# DA14682 register map
Vendor: Dialog; Series: DA14682; File version: 1.2
CPU: CM0 r1p0, little endian, MPU, FPU, 3 interrupt priority bits
Registers are 16-bit, read-write, reset 0x0 unless marked. A register's access mark holds for its fields unless they carry their own. Offsets are from the block's base; [hi:lo] are bit positions; {n}, {i} and the like mark numbered series; 'fields as' and 'values as' point back to an identical list.

## FTDF — FTDF registers
Base 0x40080000
{0x0+0x80*i} FTDF_TX_FIFO_{i}_0_REG 32-bit (reset mask 0x7FFFFFFF) (i=0..3) — Address transmit fifo {i}
  [31:0] TX_FIFO — Transmit fifo buffer, contains 32 addresses per entry (32b x 32a = 128B). There are 4 entries supported. Note that, despite the name, this fifo is NOT retained when the LMAC is put into deep-sleep!
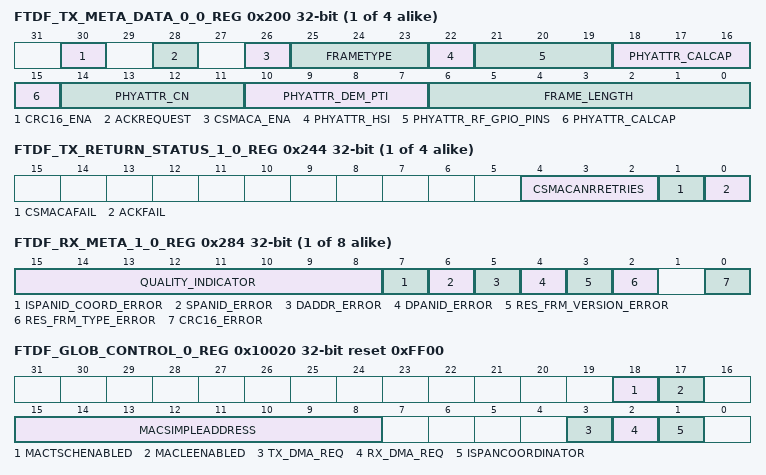
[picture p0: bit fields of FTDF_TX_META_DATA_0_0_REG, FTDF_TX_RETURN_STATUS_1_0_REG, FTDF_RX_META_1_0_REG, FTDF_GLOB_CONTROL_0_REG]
{0x200+0x10*i} FTDF_TX_META_DATA_0_{i}_REG 32-bit (i=0..3) — Transmit metadata register {i}
  [30] CRC16_ENA — Tx meta data per entry: Indicates whether CRC16 insertion must be enabled or not. 0 : No hardware inserted CRC16 1 : Hardware inserts CRC16
  [28] ACKREQUEST — Tx meta data per entry: '1' indicates that an acknowledge is expected from the recipient of this packet.
  [26] CSMACA_ENA — Tx meta data per entry: '1' indicates that a CSMA-CA is required for the transmission of this packet.
  [25:23] FRAMETYPE — Tx meta data per entry: the frame type of the data to be transmitted (Data/Cmd/Ack/wakeup frame/etc.).
  [22] PHYATTR_HSI — HighSide injection.
  [21:19] PHYATTR_RF_GPIO_PINS — Slot-basis signals mapped on GPIO via PPA.
  [18:15] PHYATTR_CALCAP — CalCap value.
  [14:11] PHYATTR_CN — Channel Number.
  [10:7] PHYATTR_DEM_PTI — DEM packet information.
  [6:0] FRAME_LENGTH — Tx meta data per entry: Frame length (in bytes)
{0x204+0x10*i} FTDF_TX_META_DATA_1_{i}_REG 32-bit (i=0..3) — Transmit metadata register {i}
  [7:0] MACSN — Tx meta data per entry: Sequence Number of this packet.
{0x240+0x10*i} FTDF_TX_RETURN_STATUS_0_{i}_REG 32-bit (reset mask 0x7FFFFFFF) (i=0..3) — Transmit status register {i}
  [31:0] TXTIMESTAMP ro — Tx return status per entry: Transmit Timestamp The Timestamp of the transmitted packet.
{0x244+0x10*i} FTDF_TX_RETURN_STATUS_1_{i}_REG 32-bit (i=0..3) — Transmit status register {i}
  [4:2] CSMACANRRETRIES ro — Tx return status per entry: Number of CSMA-CA retries before this frame has been transmitted
  [1] CSMACAFAIL ro — Tx return status per entry: CSMA-CA status 0 : SUCCESS 1 : FAIL
  [0] ACKFAIL ro — Tx return status per entry: Acknowledgement status 0 : SUCCESS 1 : FAIL
{0x280+0x10*i} FTDF_RX_META_0_{i}_REG 32-bit (reset mask 0x7FFFFFFF) (i=0..7) — Receive metadata register {i}
  [31:0] RX_TIMESTAMP ro — Rx meta data per entry: Timestamp taken when frame was received
{0x284+0x10*i} FTDF_RX_META_1_{i}_REG 32-bit (i=0..7) — Receive metadata register {i}
  [15:8] QUALITY_INDICATOR ro — Rx meta data per entry: the Link Quality Indication value during reception of this frame. # $software_scratch@retention_ram # TX ram not used by hardware, can be used by software as scratch ram with retention.
  [7] ISPANID_COORD_ERROR ro — Rx meta data per entry: if set to '1', the received frame is not for PAN coordinator, applicable when frame is not discarded
  [6] SPANID_ERROR ro — Rx meta data per entry: if set to '1', a PAN ID error has occurred, applicable when frame is not discarded
  [5] DADDR_ERROR ro — Rx meta data per entry: if set to '1', a destination Address error has occurred, applicable when frame is not discarded
  [4] DPANID_ERROR ro — Rx meta data per entry: if set to '1', a destination PAN ID error has occurred, applicable when frame is not discarded
  [3] RES_FRM_VERSION_ERROR ro — Rx meta data per entry: if set to '1' this frame is a not supported frame version, applicable when frame is not discarded.
  [2] RES_FRM_TYPE_ERROR ro — Rx meta data per entry: if set to '1' this frame is a not supported frame type, applicable when frame is not discarded
  [0] CRC16_ERROR ro — Rx meta data per entry: if set, a CRC error has occurred in this frame, applicable for transparent mode only
0x8000 FTDF_RX_FIFO_0_0_REG 32-bit (reset mask 0x7FFFFFFF) — Address receive fifo 0
  [31:0] RX_FIFO — Receive fifo ram, contains 32 addresses per entry (32b x 32a = 128B). There are 8 entries supported.
{0x8000+0x80*i} FTDF_RX_FIFO_{i}_0_REG 32-bit (reset mask 0x7FFFFFFF) (i=1..7) — Address transmit fifo {i}
  fields as FTDF_RX_FIFO_0_0_REG
{0x10000+4i} FTDF_REL_NAME_{i}_REG 32-bit (reset mask 0x7FFFFFFF) (i=0..3) — Name of the release
  [31:0] REL_NAME ro — A 4 words wide register, showing in ASCII the name of the release, eg. ftdf_107.
{0x10010+4i} FTDF_BUILDTIME_{i}_REG 32-bit (reset mask 0x7FFFFFFF) (i=0..3) — Build time
  [31:0] BUILDTIME ro — A 4 words wide register, showing in ASCII the build date (dd mmm yy) and time (hh:mm) of device, eg. 01 Dec 14 14:10.
0x10020 FTDF_GLOB_CONTROL_0_REG 32-bit reset 0xFF00 — Global control register
  [18] MACTSCHENABLED — If set to '1', the TSCH mode is enabled
  [17] MACLEENABLED — If set to '1', the Low Energy mode (also called CSL) is enabled
  [15:8] MACSIMPLEADDRESS — Simple address of the PAN coordinator
  [3] TX_DMA_REQ — Source of the TX_DMA_REQ output pin of this block.
  [2] RX_DMA_REQ — Source of the RX_DMA_REQ output pin of this block.
  [1] ISPANCOORDINATOR — Enable/disable receiver check on address fields (0=enabled, 1=disabled)
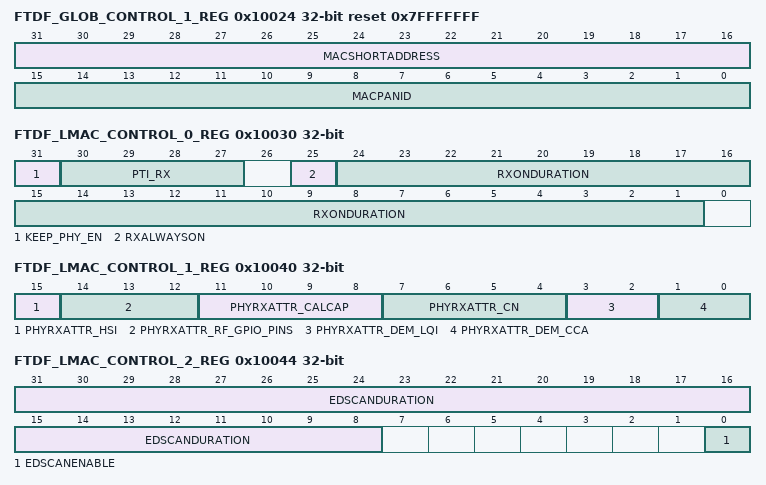
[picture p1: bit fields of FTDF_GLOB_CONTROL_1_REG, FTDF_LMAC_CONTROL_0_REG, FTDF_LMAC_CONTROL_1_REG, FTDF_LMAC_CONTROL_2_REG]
0x10024 FTDF_GLOB_CONTROL_1_REG 32-bit reset 0x7FFFFFFF (reset mask 0x7FFFFFFF) — Global control register
  [31:16] MACSHORTADDRESS — The short address of the device. The values 0xFFFF and 0xFFFE indicate that no IEEE Short Address is available.
  [15:0] MACPANID — The PAN ID of this device. The value 0xFFFF indicates that the device is not associated to a PAN.
0x10028 FTDF_GLOB_CONTROL_2_REG 32-bit reset 0x7FFFFFFF (reset mask 0x7FFFFFFF) — Global control register
  [31:0] AEXTENDEDADDRESS_L — Unique device address, 48 bits wide, lowest 32 bit
0x1002C FTDF_GLOB_CONTROL_3_REG 32-bit reset 0x7FFFFFFF (reset mask 0x7FFFFFFF) — Global control register
  [31:0] AEXTENDEDADDRESS_H — Unique device address, 48 bits wide, highest 16 bit
0x10030 FTDF_LMAC_CONTROL_0_REG 32-bit (reset mask 0x7FFFFFFF) — Lmac control register
  [31] KEEP_PHY_EN — When the transmit or receive action is ready (LmacReady4Sleep is set), the PHY_EN signal is cleared unless the control register keep_phy_en is set to '1'. When the control register keep_phy_en is set to '1', the signal PHY_EN shall remain being set until the keep_phy_en is cleared. This will help control the behavior of the arbiter between the LMAC and the DPHY.
  [30:27] PTI_RX — This value will be used during receiving frames, during the auto ACK (when the AR bit is set in the received frame, see [FR0655] and further), a single CCA and ED scan. In TSCH mode this register will be used during the time slot in which frames can be received and consequently an Enhanced ACK can be transmitted.
  [25] RXALWAYSON — If set to '1', the receiver shall be always on if RxEnable is set to '1'.
  [24:1] RXONDURATION — The time (in symbol periods) the Rx must be on after setting RxEnable to '1'.
0x10034 FTDF_TXPIPEPROPDELAY_REG 32-bit — Prop delay transmit register
  [7:0] TXPIPEPROPDELAY — Propagation delay (in us) of the tx pipe, between start of transmission (indicated by setting tx_flag_status) to the DPHY. The reset value is 0 us, which is also the closest value to the real implementation figure.
0x10038 FTDF_MACACKWAITDURATION_REG 32-bit reset 0x36 — Maximum time to wait for a ACK
  [7:0] MACACKWAITDURATION — Maximum time (in symbol periods) to wait for an ACK response after transmitting a frame with the AR bit set to '1'. This value is used in the normal mode for the wait of an ACK response, irrespective if the ACK is a normal ACK or an Enhanced ACK.
0x1003C FTDF_MACENHACKWAITDURATION_REG 32-bit reset 0x360 — Maximum time to wait for an enhanced ACK frame
  [15:0] MACENHACKWAITDURATION — Maximum time (in us) to wait for an Enhanced ACK response after transmitting a frame with the AR bit set to '1'. This value is used in the LE/CSL mode for the wait of an ACK response (which is always an Enhanced ACK).
0x10040 FTDF_LMAC_CONTROL_1_REG 32-bit — Lmac control register
  [15] PHYRXATTR_HSI — HighSide injection.
  [14:12] PHYRXATTR_RF_GPIO_PINS — Slot-basis signals mapped on GPIO via PPA.
  [11:8] PHYRXATTR_CALCAP — CalCap value.
  [7:4] PHYRXATTR_CN — Channel Number.
  [3:2] PHYRXATTR_DEM_LQI — Select the LQI calculation
  [1:0] PHYRXATTR_DEM_CCA
0x10044 FTDF_LMAC_CONTROL_2_REG 32-bit (reset mask 0x7FFFFFFF) — Lmac control register
  [31:8] EDSCANDURATION — The length of ED scan in symbol periods.
  [0] EDSCANENABLE — If set to '1', the Energy Detect scan will be performed when RxEnable is set to '1' rather than starting a receive action. The length of this scan is defined by EdScanDuration.
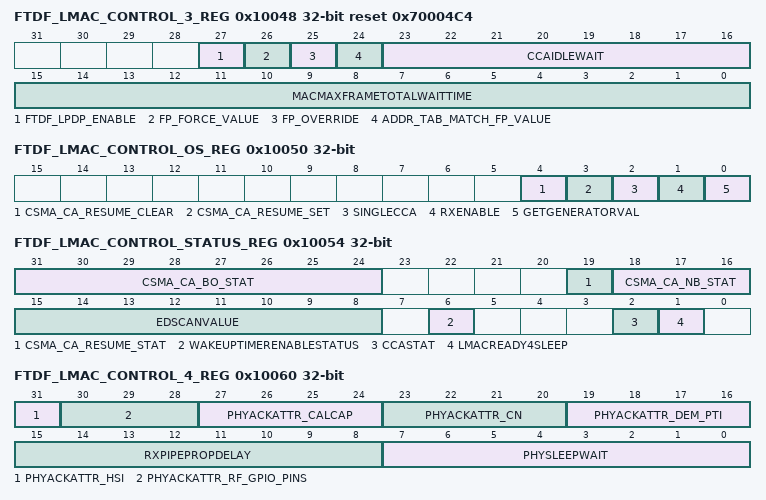
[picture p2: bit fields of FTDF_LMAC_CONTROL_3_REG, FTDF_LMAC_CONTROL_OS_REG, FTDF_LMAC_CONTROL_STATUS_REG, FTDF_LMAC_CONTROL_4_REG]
0x10048 FTDF_LMAC_CONTROL_3_REG 32-bit reset 0x70004C4 — Lmac control register
  [27] FTDF_LPDP_ENABLE — If set, not only is FP_override and SA matching done on data_request frames but to all command and data frame types (in normal mode)
  [26] FP_FORCE_VALUE — In case the control register FP_override is set, the value of the control register FP_force_value will always be the value of the FP bit in the automatic ACK response frame.
  [25] FP_OVERRIDE — In case the control register FP_override is set, the value of the control register FP_force_value will always be the value of the FP bit in the automatic ACK response frame.
  [24] ADDR_TAB_MATCH_FP_VALUE — In case the received source address matches with one of the Exp_SA registers, the value of the control register Addr_tap_match_FP_value will be inserted on the position of the FP bit. In case there is no match found, the inverse value of Addr_tap_match_FP_value will be inserted.
  [23:16] CCAIDLEWAIT — Time to wait (in us) after CCA returned medium idle before starting TX-ON. Notes: 1) extra wait times are involved before a packet is really transmitted, see the relevant timing figures. 2) not applicable in TSCH mode since there macTSRxTx shall be used.
  [15:0] MACMAXFRAMETOTALWAITTIME — Max time to wait (in symbol periods) for a requested Data Frame or an announced broadcast frame, triggered by the FP bit in the received frame was set to '1'.
0x10050 FTDF_LMAC_CONTROL_OS_REG 32-bit — Lmac control register
  [4] CSMA_CA_RESUME_CLEAR wo — If set, Csma_Ca_resume_stat is cleared
  [3] CSMA_CA_RESUME_SET wo — If set, Csma_Ca_resume_stat is set
  [2] SINGLECCA wo — If set to '1', a single CCA will be performed. This can be used when e.g. the TSCH timing is not performed by the LMAC but completely by software.
  [1] RXENABLE wo — If set, receiving data may be done
  [0] GETGENERATORVAL wo — If set to '1', the current values of the Wake-up (event) counter/generator (EventCurrVal) and Timestamp (symbol) counter/generator (TimeStampCurrVal and TimeStampCurrPhaseVal) will be captured. Note that this capture actually has been done when getGeneratorVal_e is set (assuming it was cleared in advance).
0x10054 FTDF_LMAC_CONTROL_STATUS_REG 32-bit (reset mask 0x7FFFFFFF) — Lmac status register
  [31:24] CSMA_CA_BO_STAT ro — The value of the currently calculated BackOff value. To be used for the sleep time calculation in case of sleep during the BackOff time.
  [19] CSMA_CA_RESUME_STAT ro — In case Csma_Ca_resume_stat is set the LMAC will - use the value of Csma_Ca_NB_val in the CSMA-CA process rather than the initial value 0d. - immediately perform CCA after the sleep, not waiting for the backoff time. - reset Csma_Ca_resume_stat when it resumes CSMA-CA after the sleep.
  [18:16] CSMA_CA_NB_STAT ro — Current status of the Number of Backoffs.
  [15:8] EDSCANVALUE ro — The result of an ED scan.
  [6] WAKEUPTIMERENABLESTATUS ro — Status of WakeupTimerEnable after being clocked by LP_CLK (showing it's effective value). WakeupTimerEnableStatus can be set by setting the one-shot register WakeupTimerEnable_set and cleared by setting the one-shot register WakeupTimerEnable_clear. When WakeupTimerEnableStatus is set (after being cleared), the event counter will be reset to 0x0. This status can be used by software since WakeupTimerEnable is used in the slow LP_CLK area. Rather than waiting for a certain number of LP_CLK periods, simply scanning this status (or enable the interrupt created by WakeupTimerEnableStatus_e) will allow software to determine if this signal has been effected. Note that the rising edge of WakeupTimerEnable will reset the Wake-up (event) counter.
  [2] CCASTAT ro — The value of a single CCA, valid when CCAstat_e is set to '1'.
  [1] LMACREADY4SLEEP ro — If set to '1' this register indicates that the LMAC is ready to go to sleep.
0x10058 FTDF_EVENTCURRVAL_REG 32-bit — Value of event generator
  [24:0] EVENTCURRVAL ro — The value of the captured Event generator (Wake-up counter) (initiated by getGeneratorVal, valid when getGeneratorVal_e is set).
0x1005C FTDF_TIMESTAMPCURRVAL_REG 32-bit (reset mask 0x7FFFFFFF) — Value of timestamp generator
  [31:0] TIMESTAMPCURRVAL ro — The value of captured timestamp generator (symbol counter) (initiated by getGeneratorVal, valid when getGeneratorVal_e is set)
0x10060 FTDF_LMAC_CONTROL_4_REG 32-bit (reset mask 0x7FFFFFFF) — Lmac control register
  [31] PHYACKATTR_HSI — HighSide injection.
  [30:28] PHYACKATTR_RF_GPIO_PINS — Slot-basis signals mapped on GPIO via PPA.
  [27:24] PHYACKATTR_CALCAP — CalCap value.
  [23:20] PHYACKATTR_CN — Channel Number.
  [19:16] PHYACKATTR_DEM_PTI — DEM packet information.
  [15:8] RXPIPEPROPDELAY — The control register RxPipePropDelay indicates the propagation delay in ~s of the Rx pipeline between the last symbol being captured at the DPHY interface and the data valid indication to the LMAC controller.
  [7:0] PHYSLEEPWAIT — The minume time (in us) required between the clear to '0' and set to '1' of PHY_EN. When the signal PHY_EN is deasserted, it will not be asserted within the time phySleepWait.
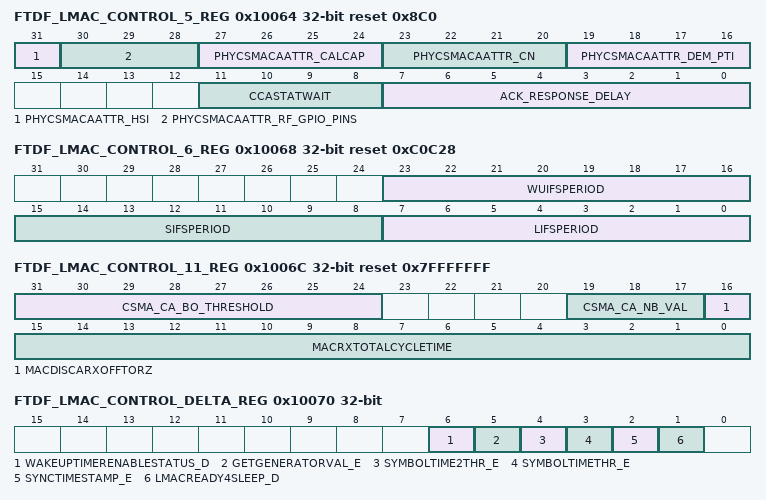
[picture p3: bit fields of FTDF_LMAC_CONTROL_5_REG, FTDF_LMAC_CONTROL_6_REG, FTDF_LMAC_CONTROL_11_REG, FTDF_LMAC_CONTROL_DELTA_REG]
0x10064 FTDF_LMAC_CONTROL_5_REG 32-bit reset 0x8C0 (reset mask 0x7FFFFFFF) — Lmac control register
  [31] PHYCSMACAATTR_HSI — HighSide injection.
  [30:28] PHYCSMACAATTR_RF_GPIO_PINS — Slot-basis signals mapped on GPIO via PPA.
  [27:24] PHYCSMACAATTR_CALCAP — CalCap value.
  [23:20] PHYCSMACAATTR_CN — Channel Number.
  [19:16] PHYCSMACAATTR_DEM_PTI — DEM packet information.
  [11:8] CCASTATWAIT — The output CCASTAT is valid after 8 symbols + phyRxStartup. The 8 symbols are programmable by control registerCcaStatWait (in symbol periods). Default value is 8d.
  [7:0] ACK_RESPONSE_DELAY — In order to have some flexibility the control register Ack_Response_Delay indicates the Acknowledge response time in ~s. The default value shall is 192 ~s (12 symbols).
0x10068 FTDF_LMAC_CONTROL_6_REG 32-bit reset 0xC0C28 — Lmac control register
  [23:16] WUIFSPERIOD — The WakeUp IFS period is programmable by WUifsPeriod (in symbols). The default is 12 symbols (192 us).
  [15:8] SIFSPERIOD — The Short IFS period is programmable by SifsPeriod (in symbols). The default is 12 symbols (192 is).
  [7:0] LIFSPERIOD — The Long IFS period is programmable by LifsPeriod (in symbols). The default is 40 symbols (640 us),
0x1006C FTDF_LMAC_CONTROL_11_REG 32-bit reset 0x7FFFFFFF (reset mask 0x7FFFFFFF) — Lmac control register
  [31:24] CSMA_CA_BO_THRESHOLD — If the backoff time calculated in the CSMA-CA procedure as described in [FR3280] is equal to or higher than the control register Csma_Ca_BO_threshold[8] (resolution 320us, see [FR3290]) the event register Csma_Ca_BO_thr_e will be set and an interrupt. In case Csma_Ca_BO_threshold equals 0xFF no check will be performed and consequently Csma_Ca_BO_thr_e will not be set and no interrupt will be generated.
  [19:17] CSMA_CA_NB_VAL — Number of backoffs value in case of a CSMA-CA resume action.
  [16] MACDISCARXOFFTORZ — The switching off and on of the PHY Rx (see macRxTotalCycleTime) can be disabled whith the control register macDisCaRxOfftoRZ. 0 : Disabled 1 : Enabled
  [15:0] MACRXTOTALCYCLETIME — In CSL mode it can be decided to disable the PHY Rx (Rx-off) after reception of a Wake-up frame and enable the PHY Rx (Rx-on) when the data frame is to be expected, based on the received RZ time. In order to make it easier to calculate if it is efficient to switch to Rx-off and Rx-on again, a control register indicates the time needed to disable and enable the PHY Rx: macRxTotalCycleTime (resolution is 10 symbol periods)
0x10070 FTDF_LMAC_CONTROL_DELTA_REG 32-bit — Lmac delta control register
  [6] WAKEUPTIMERENABLESTATUS_D — Delta which indicates that WakeupTimerEnableStatus has changed This delta bit is set to '1' on each change of this status, contributes to ftdf_ce[3].
  [5] GETGENERATORVAL_E — Event, set to '1' to indicate that the the getGeneratorVal request is completed. This event bit contributes to ftdf_ce[3].
  [4] SYMBOLTIME2THR_E — Event, set to '1' when the symboltime counter matched SymbolTime2Thr This event bit contributes to ftdf_ce[3].
  [3] SYMBOLTIMETHR_E — Event, set to '1' when the symboltime counter matched SymbolTimeThr This event bit contributes to ftdf_ce[3].
  [2] SYNCTIMESTAMP_E — The SyncTimeStamp_e event is set to '1' when the TimeStampgenerator is loaded with SyncTimeStampVal. This occurs at the rising edge of lp_clk when SyncTimeStampEna is set and the value of the Event generator is equal to the value SyncTimestampThr. This event bit contributes to ftdf_ce[3].
  [1] LMACREADY4SLEEP_D — Delta bit for register LmacReady4sleep. This delta bit is set to '1' on each change of this status, contributes to ftdf_ce[3].
0x10074 FTDF_TIMESTAMPCURRPHASEVAL_REG 32-bit — Value of timestamp generator phase within a symbol
  [7:0] TIMESTAMPCURRPHASEVAL ro — Value of captured timestamp generator phase within a symbol (initiated by getGeneratorVal, valid when getGeneratorVal_e is set)
0x10078 FTDF_MACTSTXACKDELAYVAL_REG 32-bit — Time left until next ACK is sent (us)
  [15:0] MACTSTXACKDELAYVAL ro — The time (in us) left until the ack frame is sent by the lmac. This can be used by software to determine if there is enough time left to send the, by software created, Enhanced ACK frame.
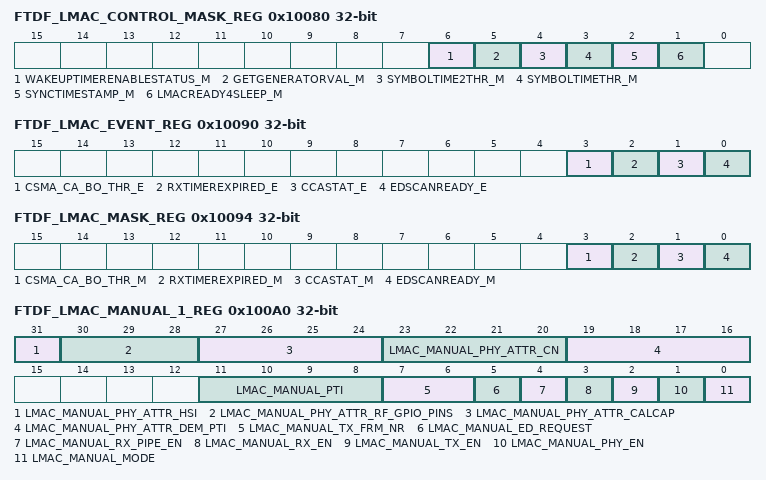
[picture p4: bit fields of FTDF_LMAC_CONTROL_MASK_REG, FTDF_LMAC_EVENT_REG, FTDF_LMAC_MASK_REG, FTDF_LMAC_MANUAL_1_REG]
0x10080 FTDF_LMAC_CONTROL_MASK_REG 32-bit — Lmac mask control register
  [6] WAKEUPTIMERENABLESTATUS_M — Mask for WakeupTimerEnableStatus_d The mask bit is masking when cleared to '0' (default value) and will enable the contribution to the interrupt when set to '1'.
  [5] GETGENERATORVAL_M — Mask for getGeneratorVal_e The mask bit is masking when cleared to '0' (default value) and will enable the contribution to the interrupt when set to '1'.
  [4] SYMBOLTIME2THR_M — Mask for SymbolTime2Thr_e The mask bit is masking when cleared to '0' (default value) and will enable the contribution to the interrupt when set to '1'.
  [3] SYMBOLTIMETHR_M — Mask for SymbolTimeThr_e The mask bit is masking when cleared to '0' (default value) and will enable the contribution to the interrupt when set to '1'.
  [2] SYNCTIMESTAMP_M — Mask bit for event register SyncTimeStamp_e. The mask bit is masking when cleared to '0' (default value) and will enable the contribution to the interrupt when set to '1'.
  [1] LMACREADY4SLEEP_M — Mask bit for delta bit LmacReady4sleep_d. The mask bit is masking when cleared to '0' (default value) and will enable the contribution to the interrupt when set to '1'.
0x10090 FTDF_LMAC_EVENT_REG 32-bit — Lmac event regsiter
  [3] CSMA_CA_BO_THR_E — If set, the calculated backoff time is more than Csma_Ca_BO_threshold. This event bit contributes to ftdf_ce[1].
  [2] RXTIMEREXPIRED_E — Set to '1' if one of the timers enabling the Rx-on mode expires without having received any valid frame. This event bit contributes to ftdf_ce[1].
  [1] CCASTAT_E — If set to '1', the single CCA is ready This event bit contributes to ftdf_ce[1].
  [0] EDSCANREADY_E — The event EdScanReady_e is set to '1' to notify that the ED scan is ready. This event bit contributes to ftdf_ce[1].
0x10094 FTDF_LMAC_MASK_REG 32-bit — Lmac mask register
  [3] CSMA_CA_BO_THR_M — Mask bit for event Csma_Ca_BO_thr_e The mask bit is masking when cleared to '0' (default value) and will enable the contribution to the interrupt when set to '1'.
  [2] RXTIMEREXPIRED_M — Mask bit for event RxTimerExpired_e The mask bit is masking when cleared to '0' (default value) and will enable the contribution to the interrupt when set to '1'.
  [1] CCASTAT_M — Mask bit for event CCAstat_e The mask bit is masking when cleared to '0' (default value) and will enable the contribution to the interrupt when set to '1'.
  [0] EDSCANREADY_M — Mask bit for event EdScanReady_e The mask bit is masking when cleared to '0' (default value) and will enable the contribution to the interrupt when set to '1'.
0x100A0 FTDF_LMAC_MANUAL_1_REG 32-bit (reset mask 0x7FFFFFFF) — Lmax manual PHY register
  [31] LMAC_MANUAL_PHY_ATTR_HSI — HighSide injection.
  [30:28] LMAC_MANUAL_PHY_ATTR_RF_GPIO_PINS — Slot-basis signals mapped on GPIO via PPA.
  [27:24] LMAC_MANUAL_PHY_ATTR_CALCAP — CalCap value.
  [23:20] LMAC_MANUAL_PHY_ATTR_CN — Channel Number.
  [19:16] LMAC_MANUAL_PHY_ATTR_DEM_PTI — DEM packet information.
  [11:8] LMAC_MANUAL_PTI — lmac_manual_pti controls the PTI interface signal when lmac_manual_mode is set to '1'.
  [7:6] LMAC_MANUAL_TX_FRM_NR — lmac_manual_tx_frm_nr controls the entry in the tx buffer to be transmitted when lmac_manual_mode is set to '1'.
  [5] LMAC_MANUAL_ED_REQUEST — lmac_manual_ed_request controls the ED_REQUEST interface signal when lmac_manual_mode is set to '1'.
  [4] LMAC_MANUAL_RX_PIPE_EN — lmac_manual_rx_pipe_en controls the rx_enable signal towards the rx pipeline when lmac_manual_mode is set to '1'.
  [3] LMAC_MANUAL_RX_EN — lmac_manual_rx_en controls the RX_EN interface signal when lmac_manual_mode is set to '1'.
  [2] LMAC_MANUAL_TX_EN — lmac_manual_tx_en controls the TX_EN interface signal when lmac_manual_mode is set to '1'.
  [1] LMAC_MANUAL_PHY_EN — lmac_manual_phy_en controls the PHY_EN interface signal when lmac_manual_mode is set to '1'.
  [0] LMAC_MANUAL_MODE — If the control register lmac_manual_mode is set to '1', the LMAC controller control signals should be controlled by the lmac_manual_control registers
0x100A4 FTDF_LMAC_MANUAL_OS_REG 32-bit — One shot register triggers transmission in manual mode
  [0] LMAC_MANUAL_TX_START wo — One shot register which triggers the transmission of a frame from the tx buffer in lmac_manual_mode to '1'.
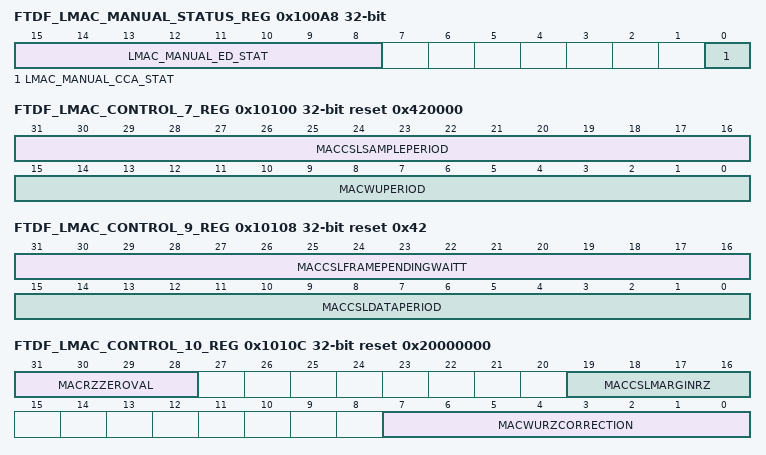
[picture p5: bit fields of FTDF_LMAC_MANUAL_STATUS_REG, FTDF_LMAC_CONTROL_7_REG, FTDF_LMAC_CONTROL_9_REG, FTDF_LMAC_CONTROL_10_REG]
0x100A8 FTDF_LMAC_MANUAL_STATUS_REG 32-bit — Lmac status register in manual mode
  [15:8] LMAC_MANUAL_ED_STAT ro — lmac_manual_ed_stat shows the status of the ED_STAT DPHY interface signal.
  [0] LMAC_MANUAL_CCA_STAT ro — lmac_manual_cca_stat shows the status of the CCA_STAT DPHY interface signal.
0x10100 FTDF_LMAC_CONTROL_7_REG 32-bit reset 0x420000 (reset mask 0x7FFFFFFF) — Lmac control register
  [31:16] MACCSLSAMPLEPERIOD — In CSL mode, when performing a idle listening, the receiver is enabled for at least macCSLsamplePeriod (in symbol oeriods).
  [15:0] MACWUPERIOD — In CSL mode, the Wake-up duration in symbol periods. During this period, Wake-up frames will be transmitted.
0x10104 FTDF_LMAC_CONTROL_8_REG 32-bit (reset mask 0x7FFFFFFF) — Lmac control register
  [31:0] MACCSLSTARTSAMPLETIME — In CSL mode, the control register macCSLstartSampleTime indicates the TimeStamp generator time (in symbol periods) when to start listening (called idle listening) or transmitting (when tx_flag_status is set).
0x10108 FTDF_LMAC_CONTROL_9_REG 32-bit reset 0x42 (reset mask 0x7FFFFFFF) — Lmac control register
  [31:16] MACCSLFRAMEPENDINGWAITT — In CSL mode, if a non Wake-up frame with Frame Pending bit = '1' is received, the receiver is enabled for at least an extra period of macCSLFramePendingWaitT (in symbol periods) after the end of the received frame. The time the Enhanced ACK transmission lasts (if applicable) is included in this time.
  [15:0] MACCSLDATAPERIOD — In CSL mode, after the wake-up sequence a data frame is expected. The receiver will be enabled for at least a period of macCSLdataPeriod (in symbol periods).
0x1010C FTDF_LMAC_CONTROL_10_REG 32-bit reset 0x20000000 (reset mask 0x7FFFFFFF) — Lmac control register
  [31:28] MACRZZEROVAL — In CSL mode, if the current RZtime is less or Equal to macRZzeroVal an RZtime with value zero is inserted in the wakeup frame. So this is by default the last Wake-up frame of a Wake-up sequence.
  [19:16] MACCSLMARGINRZ — In CSL mode, the software can set the margin for the expected frame by control register macCSLmarginRZ (in 10 symbol periods). The LMAC will make sure that the receiver is ready to receive data this amount of time earlier than to be expected by the received RZ time.
  [7:0] MACWURZCORRECTION — In CSL mode, this register shall be used if the Wake-up frame to be transmitted is larger than 15 octets. It shall indicate the amount of extra data in a Wake-up frame after the RZ position in the frame (in 10 symbol periods). This correction is needed to make sure that the correct RZ time is filled in by the LMAC.
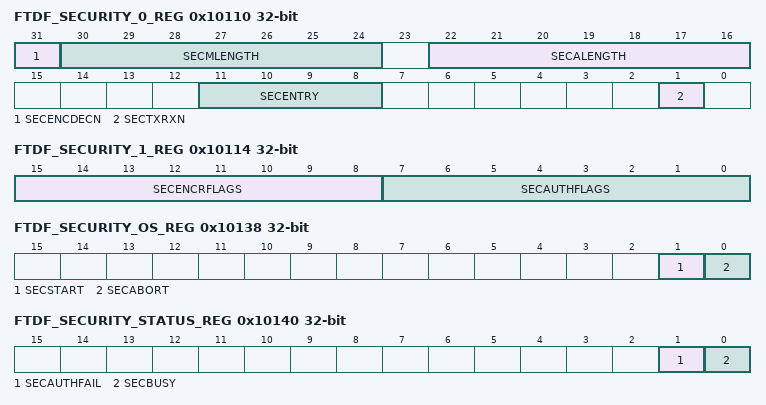
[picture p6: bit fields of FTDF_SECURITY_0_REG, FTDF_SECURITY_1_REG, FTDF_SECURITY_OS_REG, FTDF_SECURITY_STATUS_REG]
0x10110 FTDF_SECURITY_0_REG 32-bit (reset mask 0x7FFFFFFF) — Security register
  [31] SECENCDECN — Encryption/decryption mode: the control register secEncDecn indicates whether to encrypt ('1') or decrypt ('0') the data.
  [30:24] SECMLENGTH — Encryption/decryption mode: the length of the m_data is indicated by control register secMlength (in bytes).
  [22:16] SECALENGTH — Encryption/decryption mode: the length of the a_data is indicated by control register secAlength (in bytes). The end of the a_data is the start point of the m_data. So secAlength must also be set if security level==4.
  [11:8] SECENTRY — Encryption/decryption mode: the software indicates by the control registers secEntry and secTxRxn which entry to use and if it's from the Tx or Rx buffer ('1' resp. '0').
  [1] SECTXRXN — Encryption/decryption mode: see register secEntry.
0x10114 FTDF_SECURITY_1_REG 32-bit — Security register
  [15:8] SECENCRFLAGS — Encryption/decryption mode: register secEncrFlags contains the encryption flags field. Bits [2:0] are the 3-bit encoding flags of a_data, the other bits msut be set to '0'.
  [7:0] SECAUTHFLAGS — Encryption/decryption mode: register secAuthFlags contains the authentication flags fields. bit[7] is '0' bit[6] is A_data present bit[5:3]: 3-bit security level of m_data bit[2:0]: 3-bit security level of a_data.
0x10118 FTDF_SECKEY_0_REG 32-bit (reset mask 0x7FFFFFFF) — Seckey register
  [31:0] SECKEY_0 — Encryption/decryption mode: Registers secKey[0..3] contain the key to be used.
0x1011C FTDF_SECKEY_1_REG 32-bit (reset mask 0x7FFFFFFF) — Seckey register
  [31:0] SECKEY_1 — Encryption/decryption mode: see register secKey_0
0x10120 FTDF_SECKEY_2_REG 32-bit (reset mask 0x7FFFFFFF) — SecKey register
  [31:0] SECKEY_2 — Encryption/decryption mode: see register secKey_0
0x10124 FTDF_SECKEY_3_REG 32-bit (reset mask 0x7FFFFFFF) — Seckey register
  [31:0] SECKEY_3 — Encryption/decryption mode: see register secKey_0
0x10128 FTDF_SECNONCE_0_REG 32-bit (reset mask 0x7FFFFFFF) — Nonce register used for encryption/decryption
  [31:0] SECNONCE_0 — Encryption/decryption mode: register secNonce[0..3] contains the Nonce to be used for encryption/decryption.
0x1012C FTDF_SECNONCE_1_REG 32-bit (reset mask 0x7FFFFFFF) — Nonce register used for encryption/decryption
  [31:0] SECNONCE_1 — Encryption/decryption mode: see register Nonce_0
0x10130 FTDF_SECNONCE_2_REG 32-bit (reset mask 0x7FFFFFFF) — Nonce register used for encryption/decryption
  [31:0] SECNONCE_2 — Encryption/decryption mode: see register Nonce_0
0x10134 FTDF_SECNONCE_3_REG 32-bit — Nonce register used for encryption/decryption
  [7:0] SECNONCE_3 — Encryption/decryption mode: see register Nonce_0
0x10138 FTDF_SECURITY_OS_REG 32-bit — One shot register to start encryption/decryption
  [1] SECSTART wo — Encryption/decryption mode: one_shot register to start the encryption, decryption and authentication support task.
  [0] SECABORT wo — Encryption/decryption mode: see register Nonce_0
0x10140 FTDF_SECURITY_STATUS_REG 32-bit — Security status register
  [1] SECAUTHFAIL ro — Encryption/decryption mode: in case of decryption, the status bit secAuthFail will be set when the authentication has failed.
  [0] SECBUSY ro — Encryption/decryption mode: register secBusy indicates if the encryption/decryption process is still running.
0x10150 FTDF_SECURITY_EVENT_REG 32-bit — security event register
  [0] SECREADY_E — Encryption/decryption mode: the Event bit secReady_e is set to '1' when the authentication process is ready (i.e. secBusy is cleared). This event bit contributes to ftdf_ce[3].
0x10154 FTDF_SECURITY_EVENTMASK_REG 32-bit — security event mask register
  [0] SECREADY_M — Mask bit for event secReady_e The mask bit is masking when cleared to '0' (default value) and will enable the contribution to the interrupt when set to '1'.
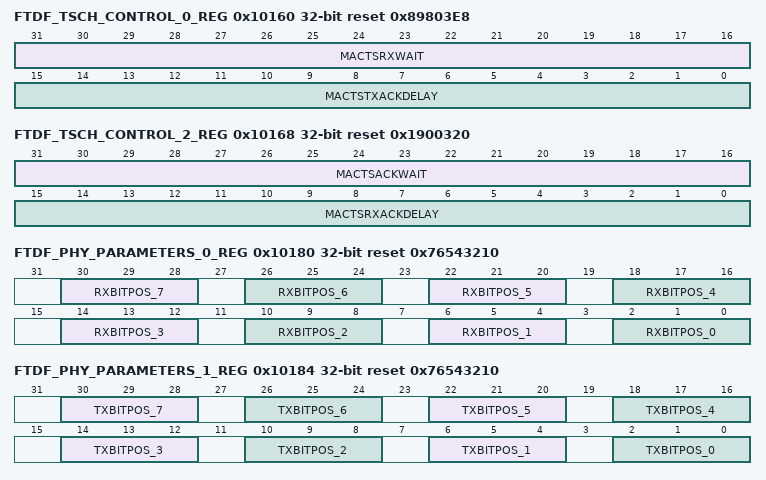
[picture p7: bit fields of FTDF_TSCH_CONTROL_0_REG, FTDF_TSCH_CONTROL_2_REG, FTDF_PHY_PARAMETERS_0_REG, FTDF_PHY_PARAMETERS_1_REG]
0x10160 FTDF_TSCH_CONTROL_0_REG 32-bit reset 0x89803E8 (reset mask 0x7FFFFFFF) — Lmac tsch control register
  [31:16] MACTSRXWAIT — TSCH mode: The times to wait for start of frame
  [15:0] MACTSTXACKDELAY — TSCH mode: the time between the end of a Rx frame and the start of an Enhanced Acknowlegde frame.
0x10164 FTDF_TSCH_CONTROL_1_REG 32-bit reset 0xC0 — Lmac tsch control register
  [15:0] MACTSRXTX — TSCH mode: The time between the CCA and the TX of a frame
0x10168 FTDF_TSCH_CONTROL_2_REG 32-bit reset 0x1900320 (reset mask 0x7FFFFFFF) — Lmac tsch control register
  [31:16] MACTSACKWAIT — TSCH mode: The minimum time to wait for start of an Acknowledgement
  [15:0] MACTSRXACKDELAY — TSCH mode: End of frame to when the transmitter shall listen for Acknowledgement
0x10180 FTDF_PHY_PARAMETERS_0_REG 32-bit reset 0x76543210 — Lmac PHY parameter register
  [4n+2:4n] RXBITPOS_{n} (n=1..7) — DPHY interface: see rxBitPos_0
  [2:0] RXBITPOS_0 — DPHY interface: control rxBitPos(8)(3) controls the position that a bit should have at the DPHY interface. So the default values are rxBitPos_0 = 0, rxBitPos_1 = 1, rxBitPos_2 = 2, etc. Note1 that this is a conversion from rx DPHY interface to the internal data byte So for(n=7;n>=0;n--) rx_data(n) = dphy_bit(tx_BitPos(n)) endfor Note2 that rxBitPos and txBitPos must have inverse functions.
0x10184 FTDF_PHY_PARAMETERS_1_REG 32-bit reset 0x76543210 — Lmac PHY parameter register
  [4n+2:4n] TXBITPOS_{n} (n=1..7) — DPHY interface: see txBitPos_0
  [2:0] TXBITPOS_0 — DPHY interface: control txBitPos(8)(3) controls the position that a bit should have at the DPHY interface. So the default values are txBitPos_0 = 0, txBitPos_1 = 1, txBitPos_2 = 2, etc. Note1 that this is a conversion from internal data byte to the DPHY interface. So for(n=7;n>=0;n--) tx_dphy_bit(n) = tx_data(tx_BitPos(n)) endfor Note2 that txBitPos and rxBitPos must have inverse functions.
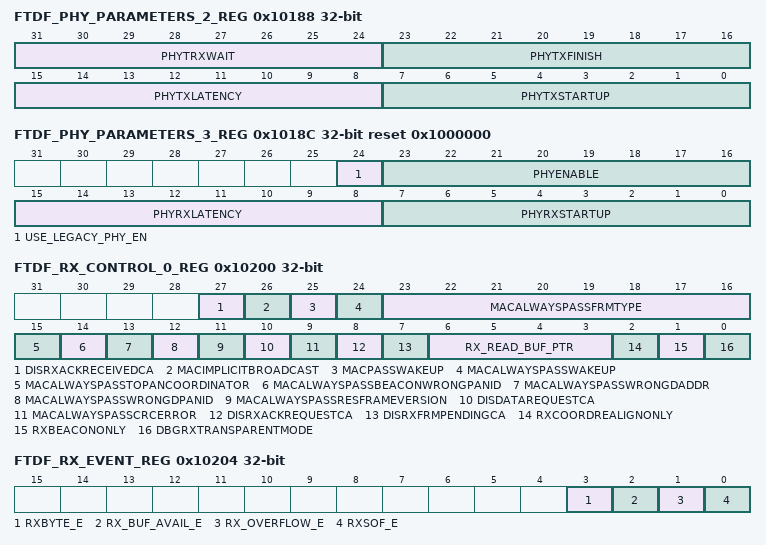
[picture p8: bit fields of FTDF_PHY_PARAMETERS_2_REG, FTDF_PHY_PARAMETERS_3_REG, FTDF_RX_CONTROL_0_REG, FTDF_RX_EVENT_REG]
0x10188 FTDF_PHY_PARAMETERS_2_REG 32-bit (reset mask 0x7FFFFFFF) — Lmac PHY parameter register
  [31:24] PHYTRXWAIT — DPHY interface: Phy wait time (in us) between deassertion of TX_EN and assertion of RX_EN or vice versa.
  [23:16] PHYTXFINISH — DPHY interface: Phy wait time (in us) before deasserting TX_EN after deasserting TX_VALID.
  [15:8] PHYTXLATENCY — DPHY interface: phy delay (in us) between DPHY interface and air interface.
  [7:0] PHYTXSTARTUP — DPHY interface: the phy wait time (in us) before transmission of a frame may start.
0x1018C FTDF_PHY_PARAMETERS_3_REG 32-bit reset 0x1000000 — Lmac PHY parameter register
  [24] USE_LEGACY_PHY_EN — If the control register use_legacy_phy_en is set (default), the output signal PHY_TRANSACTION will be sourced by PHY_EN rather than PHY_TRANSACTION.
  [23:16] PHYENABLE — DPHY interface: Asserting the DPHY interface signals TX_EN or RX_EN does not take place within the time phyEnable after asserting the signal PHY_EN. (in us).
  [15:8] PHYRXLATENCY — DPHY interface: Phy delay (in us) between air and DPHY interface.
  [7:0] PHYRXSTARTUP — DPHY interface: Phy wait time (in us) before receiving of a frame may start.
0x10200 FTDF_RX_CONTROL_0_REG 32-bit — Receive control register
  [27] DISRXACKRECEIVEDCA — If set to '1', the LMAC controller shall ignore all consequent actions upon a set AR bit in the transmitted frame (e.g. enabling Rx-on mode after the transmission and wait for an ACK).
  [26] MACIMPLICITBROADCAST — If set to '1', Frame Version 2 frames without Daddr or DPANId shall be accepted.
  [25] MACPASSWAKEUP — In CSL mode, if set to '1', WakeUp frames will be put into the Rx buffer. This can be useful for software to parse the WakeUp frame.
  [24] MACALWAYSPASSWAKEUP — In CSL mode, if the control register macAlwaysPassWakeUp is set to '1', received Wake- up frames for this device are put into the Rx packet buffer without notifying the LMAC Controller (part of transparent mode control).
  [23:16] MACALWAYSPASSFRMTYPE — The control registers macAlwaysPassFrmType[7:0], shall control if this Frame Type shall be dropped. If a bit is set to '1', the Frame Type corresponding with the bit position is not dropped, even in case of a CRC error. Example: if bit 3 is set to '1', Frame Type 3 shall not be dropped. If there is a FCS error, the error shall be reported in the Rx meta data (crc16_error is set to '1').
  [15] MACALWAYSPASSTOPANCOORDINATOR — When the control register macAlwaysPassToPanCoordinator is set to '1', the frame is not dropped due to a span_coord_error. However, in case of an FCS error, the packet is dropped.
  [14] MACALWAYSPASSBEACONWRONGPANID — If the control register macAlwaysPassBeaconWrongPANId is set, the frame is not dropped in case of a mismatch in PAN-ID, irrespective of the setting of RxBeaconOnly.
  [13] MACALWAYSPASSWRONGDADDR — If set to '1', a packet with a wrong DAddr is not dropped
  [12] MACALWAYSPASSWRONGDPANID — If register macAlwaysPassWrongDPANId is set to '1', packet with a wrong Destiantion PanID will not be dropped. However, in case of an FCS error, the packet is dropped.
  [11] MACALWAYSPASSRESFRAMEVERSION — If set to '1', a packet with a reserved FrameVersion shall not be dropped
  [10] DISDATAREQUESTCA — When the control register DisDataRequestCa is set, the notification of the received Data Request is disabled.
  [9] MACALWAYSPASSCRCERROR — If set to '1', a FCS error will not drop the frame. However, an FCS error will be reported in the Rx meta data (crc16_error is set to '1').
  [8] DISRXACKREQUESTCA — When the control register DisRxAckRequestca is set to '1' all consequent actions for a received Acknowledge Request bit are disabled.
  [7] DISRXFRMPENDINGCA — Whan the control register DisRxFrmPendingCa is set to '1', the notification of the received FP bit to the LMAC Controller is disabled and thus no consequent actions will take place.
  [6:3] RX_READ_BUF_PTR — Indication where new data will be read All four bits shall be used when using these pointer values (0d - 15d). However, the Receive Packet buffer has a size of 8 entries. So reading the Receive Packet buffer entries shall use the mod8 of the pointer values.
  [2] RXCOORDREALIGNONLY — If set to '1', only Coordinator Realignment frames are accepted
  [1] RXBEACONONLY — If set to '1', only Beacons frames are accepted
  [0] DBGRXTRANSPARENTMODE — If set yo '1', Rx pipe is fully set in transparent mode (for debug purpose).
0x10204 FTDF_RX_EVENT_REG 32-bit — Receive event register
  [3] RXBYTE_E — If set to '1' it indicates that the first byte of a new packet has been received This event bit contributes to ftdf_ce[1].
  [2] RX_BUF_AVAIL_E — If set to '1' it indicates that a new valid packet has been completely received This event bit contributes to ftdf_ce[1].
  [1] RX_OVERFLOW_E — If set to '1' it indicates that the Rx packet buffer has an overflow. This event bit contributes to ftdf_ce[1].
  [0] RXSOF_E — Set to '1' when RX_SOF has been detected. This event bit contributes to ftdf_ce[1].
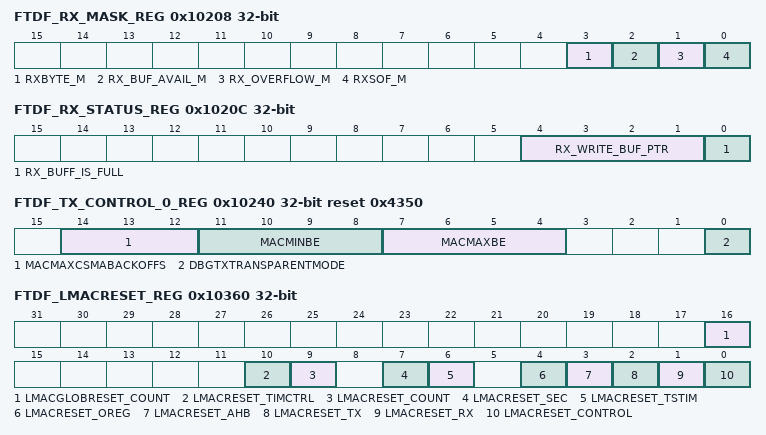
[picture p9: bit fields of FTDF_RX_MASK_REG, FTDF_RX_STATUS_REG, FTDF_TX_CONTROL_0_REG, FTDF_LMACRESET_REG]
0x10208 FTDF_RX_MASK_REG 32-bit — Receive event mask register
  [3] RXBYTE_M — Mask bit for event rxbyte_e. The mask bit is masking when cleared to '0' (default value) and will enable the contribution to the interrupt when set to '1'.
  [2] RX_BUF_AVAIL_M — Mask bit for event rx_buf_avail_e The mask bit is masking when cleared to '0' (default value) and will enable the contribution to the interrupt when set to '1'.
  [1] RX_OVERFLOW_M — Mask bit for event rx_overflow_e The mask bit is masking when cleared to '0' (default value) and will enable the contribution to the interrupt when set to '1'.
  [0] RXSOF_M — Mask bit for event RxSof_e. The mask bit is masking when cleared to '0' (default value) and will enable the contribution to the interrupt when set to '1'.
0x1020C FTDF_RX_STATUS_REG 32-bit — Receive status register
  [4:1] RX_WRITE_BUF_PTR ro — Indication where new data will be written. All four bits shall be used when using these pointer values (0d - 15d). However, the Receive Packet buffer has a size of 8 entries. So reading the Receive Packet buffer entries shall use the mod8 of the pointer values.
  [0] RX_BUFF_IS_FULL ro — If set to '1', it indicates that the Rx packet buffer is full
0x10210 FTDF_SYMBOLTIMESNAPSHOTVAL_REG 32-bit (reset mask 0x7FFFFFFF) — Value timestamp generator
  [31:0] SYMBOLTIMESNAPSHOTVAL ro — The Status register SymbolTimeSnapshotVal indicates the actual value of the TimeStamp generator. This can be useful for software to use e.g. in CSL mode at creating an Enhanced ACK to calculate the CSL phase and period.
0x10220 FTDF_RX_STATUS_DELTA_REG 32-bit — Receive status delta register
  [0] RX_BUFF_IS_FULL_D — Delta bit of status rx_buff_is_full. This delta bit is set to '1' on each change of this status, contributes to ftdf_ce[1].
0x10224 FTDF_RX_STATUS_MASK_REG 32-bit — Receive status delta mask register
  [0] RX_BUFF_IS_FULL_M — Mask bit for delta bit rx_buff_is_full_d The mask bit is masking when cleared to '0' (default value) and will enable the contribution to the interrupt when set to '1'.
0x10240 FTDF_TX_CONTROL_0_REG 32-bit reset 0x4350 — Transmit control register
  [14:12] MACMAXCSMABACKOFFS — CSMA-CA: Maximum number of CSMA-CA backoffs (range 0-5)
  [11:8] MACMINBE — CSMA-CA: Minimum Backoff Exponent (range 0-macMaxBE)
  [7:4] MACMAXBE — CSMA-CA: Maximum Backoff Exponent (range 3-8)
  [0] DBGTXTRANSPARENTMODE — If set to '1', the MPDU octets pass transparently through the MAC in the transmit direction (for debug purpose).
0x10250 FTDF_FTDF_CE_REG 32-bit — Selection register events
  [5:0] FTDF_CE ro — Composite service request from ftdf macro (see FR0400 in v40.100.2.41.pdf), set to '1' if the branch currently contributes to the interrupt. Bit 0 = unused Bit 1 = rx interrupts Bit 2 = unused Bit 3 = miscelaneous interrupts Bit 4 = tx interrupts Bit 5 = Reserved Upon an interrupt, using the ftdf_ce bits it can be checked which interrupt branch creates this interrupt.
0x10254 FTDF_FTDF_CM_REG 32-bit — Mask selection register events
  [5:0] FTDF_CM — mask bits for ftf_ce. The mask bit is masking when cleared to '0' (default value) and will enable the contribution to the interrupt when set to '1'.
0x10304 FTDF_SYNCTIMESTAMPTHR_REG 32-bit — Threshold timestamp generator
  [24:0] SYNCTIMESTAMPTHR — Threshold for synchronize the timestamp counter: at this value of the event counter the synchronization of the timestamp (symbol) counter is done (if SyncTimeStampEna is set to '1'). If SyncTimeStamp_e is set to '1' the synchronization has taken place.
0x10308 FTDF_SYNCTIMESTAMPVAL_REG 32-bit (reset mask 0x7FFFFFFF) — Value timestamp generator
  [31:0] SYNCTIMESTAMPVAL — Value to synchronize the timestamp counter with at the moment indicated by SyncTimeStampThr.
0x1030C FTDF_TIMER_CONTROL_1_REG 32-bit — Timer control register
  [1] SYNCTIMESTAMPENA — If set to '1', the synchronization of the timestamp counter after a deep-sleep cycle will be performed when SyncTimeStampThr matches the value of the event (wake-up) counter.
0x10310 FTDF_MACTXSTDACKFRMCNT_REG 32-bit (reset mask 0x7FFFFFFF) — Transmitted acknowledgment frames
  [31:0] MACTXSTDACKFRMCNT ro — Traffic counter: the number of standard Acknowledgment frames transmitted after the last deep-sleep cycle.
0x10314 FTDF_MACRXSTDACKFRMOKCNT_REG 32-bit (reset mask 0x7FFFFFFF) — Received acknowledgment frames
  [31:0] MACRXSTDACKFRMOKCNT ro — Traffic counter: the number of Standard Acknowledgment frames received after the last deep-sleep cycle.
0x10318 FTDF_MACRXADDRFAILFRMCNT_REG 32-bit (reset mask 0x7FFFFFFF) — Discarded frames register
  [31:0] MACRXADDRFAILFRMCNT ro — Traffic counter: the number of frames discarded due to incorrect address or PAN Id after the last deep-sleep cycle.
0x1031C FTDF_MACRXUNSUPFRMCNT_REG 32-bit (reset mask 0x7FFFFFFF) — Unsupported frames register
  [31:0] MACRXUNSUPFRMCNT ro — Traffic counter: the number of frames which do pass the checks but are not supported after the last deep-sleep cycle.
0x10320 FTDF_SYNCTIMESTAMPPHASEVAL_REG 32-bit — Timestamp phase value regsiter
  [7:0] SYNCTIMESTAMPPHASEVAL — Value to synchronize the timestamp counter phase with at the moment indicated by SyncTimeStampThr. Please note the +1 correction needed for most accurate result (+0.5 is than the average error, resulting is a just too fast clock).
0x10340 FTDF_MACFCSERRORCOUNT_REG 32-bit (reset mask 0x7FFFFFFF) — Lmac FCS error register
  [31:0] MACFCSERRORCOUNT ro — metrics counter: the number of received frames that were discarded due to an incorrect FCS after the last deep-sleep cycle.
0x10360 FTDF_LMACRESET_REG 32-bit — Lmax reset register
  [16] LMACGLOBRESET_COUNT wo — If set, the LMAC performance and traffic counters will be reset. Use this register for functionally reset these counters.
  [10] LMACRESET_TIMCTRL wo — LmacReset_count: A '1' resets LMAC timing control block (for debug and MLME-reset)
  [9] LMACRESET_COUNT wo — LmacReset_count: A '1' resets LMAC mac counters (for debug and MLME-reset)
  [7] LMACRESET_SEC wo — LmacReset_sec: A '1' resets LMAC security (for debug and MLME-reset) #$LmacReset_wutim@on_off_regmap #LmacReset_wutim: A '1' Resets LMAC wake-up timer (for debug and MLME-reset)
  [6] LMACRESET_TSTIM wo — LmacReset_tstim: A '1' resets LMAC timestamp timer (for debug and MLME-reset)
  [4] LMACRESET_OREG wo — LmacReset_oreg: A '1' resets LMAC on_off regmap (for debug and MLME-reset) #$LmacReset_areg@on_off_regmap #LmacReset_areg: A '1' Resets LMAC always_on regmap (for debug and MLME-reset)
  [3] LMACRESET_AHB wo — LmacReset_ahb: A '1' resets LMAC ahb interface (for debug and MLME-reset)
  [2] LMACRESET_TX wo — LmacReset_tx: A '1' resets LMAC tx pipeline (for debug and MLME-reset)
  [1] LMACRESET_RX wo — LmacReset_rx: A '1' resets LMAC rx pipeline (for debug and MLME-reset)
  [0] LMACRESET_CONTROL wo — LmacReset_control: A '1' resets LMAC Controller (for debug and MLME-reset)
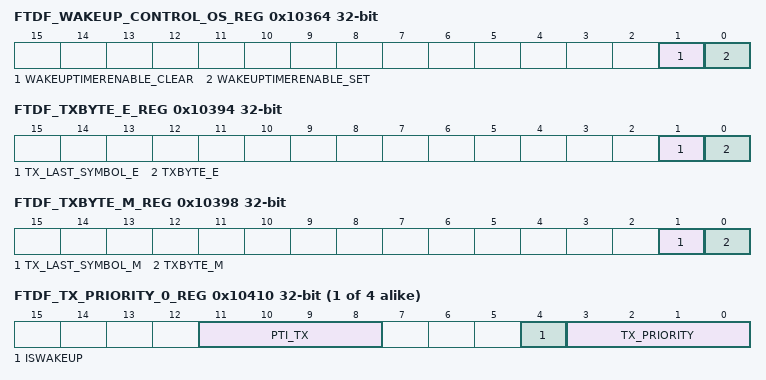
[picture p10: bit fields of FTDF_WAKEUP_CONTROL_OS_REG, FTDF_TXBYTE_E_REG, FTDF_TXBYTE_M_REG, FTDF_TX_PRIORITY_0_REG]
0x10364 FTDF_WAKEUP_CONTROL_OS_REG 32-bit
  [1] WAKEUPTIMERENABLE_CLEAR wo — If set, WakeupTimerEnableStatus will be cleared.
  [0] WAKEUPTIMERENABLE_SET wo — If set, WakeupTimerEnableStatus will be set.
0x10380 FTDF_SYMBOLTIMETHR_REG 32-bit (reset mask 0x7FFFFFFF) — Symboltime threshold register 1
  [31:0] SYMBOLTIMETHR — Symboltime Threshold to generate a general interrupt when this value matches the symbol counter value.
0x10384 FTDF_SYMBOLTIME2THR_REG 32-bit (reset mask 0x7FFFFFFF) — Symboltime threshold register 2
  [31:0] SYMBOLTIME2THR — Symboltime 2 Threshold to generate a general interrupt when this value matches the symbol counter value.
0x10390 FTDF_DEBUGCONTROL_REG 32-bit — Debug control register
  [8] DBG_RX_INPUT — If set to '1', the Rx debug interface will be selected as input for the Rx pipeline rather than the DPHY interface signals. Note that in this mode, DBG_RX_DATA[3:0] and DBG_RX_SOF are sourced by another source (outside the scope of the LMAC) while the other Rx inputs (CCA_STAT, LQI[7:0] and ED_STAT[7:0]) are forced to 0x00.
0x10394 FTDF_TXBYTE_E_REG 32-bit — Transmit first byte register
  [1] TX_LAST_SYMBOL_E — If set to '1', it indicates the last symbol of a frame is transmitted This event bit contributes to ftdf_ce[4].
  [0] TXBYTE_E — If set to '1', it indicates the first byte of a frame is transmitted This event bit contributes to ftdf_ce[4].
0x10398 FTDF_TXBYTE_M_REG 32-bit — Transmit first byte mask register
  [1] TX_LAST_SYMBOL_M — Mask bit for event tx_last_symbol_e. The mask bit is masking when cleared to '0' (default value) and will enable the contribution to the interrupt when set to '1'.
  [0] TXBYTE_M — Mask bit for event txbyte_e. The mask bit is masking when cleared to '0' (default value) and will enable the contribution to the interrupt when set to '1'.
{0x10400+0x20*i} FTDF_TX_FLAG_S_{i}_REG 32-bit (i=0..3) — Transmit packet ready for transmission register {i}
  [0] TX_FLAG_STAT ro — Tx meta data per entry: if set to '1', the packet is ready for transmission
{0x10404+0x20*i} FTDF_TX_FLAG_CLEAR_E_{i}_REG 32-bit (i=0..3) — Clear flag register {i}
  [0] TX_FLAG_CLEAR_E — Tx meta data per entry: if set to '1' the LMAC hardware has cleared the tx_flag_stat status. This event bit contributes to ftdf_ce[4].
0x10408 FTDF_TX_FLAG_CLEAR_M_0_REG 32-bit — Mask flag register 0
  [0] TX_FLAG_CLEAR_M — Tx meta data per entry: Mask bit for event tx_flag_clear_e. The mask bit is masking when cleared to '0' (default value) and will enable the contribution to the interrupt when set to '1'.
{0x10410+0x20*i} FTDF_TX_PRIORITY_{i}_REG 32-bit (i=0..3) — Transmit priority register {i}
  [11:8] PTI_TX — This register has 4 entries, belonging to the entry of the Tx frame to send, to be used during transmitting frames and the CMSA-CA phase before (when requested). In TSCH mode this register shall be used during the time slot in which frames can be transmitted and consequently an Enhanced ACK can be received. Since pti_tx belongs to a certain frame to be transmitted, pti_tx can be considered as extra Tx meta data.
  [4] ISWAKEUP — Tx meta data per entry: A basic wake-up frame can be generated by the UMAC in the Tx buffer. The meta data control bit IsWakeUp must be set to indicate that this is a Wake-up frame.
  [3:0] TX_PRIORITY — Tx meta data per entry: Priority of packet
0x10428 FTDF_TX_FLAG_CLEAR_M_1_REG 32-bit — Mask flag register 1
  [0] TX_FLAG_CLEAR_M — Tx meta data per entry: Mask bit for event tx_flag_clear_e The mask bit is masking when cleared to '0' (default value) and will enable the contribution to the interrupt when set to '1'.
0x10448 FTDF_TX_FLAG_CLEAR_M_2_REG 32-bit — Clear flag register 2
  fields as FTDF_TX_FLAG_CLEAR_M_1_REG
0x10468 FTDF_TX_FLAG_CLEAR_M_3_REG 32-bit — Clear flag register 3
  fields as FTDF_TX_FLAG_CLEAR_M_1_REG
0x10480 FTDF_TX_SET_OS_REG 32-bit — One shot register to set flag
  [3:0] TX_FLAG_SET wo — Tx meta data per entry: if set to '1', the tx_flag_stat will be set to '1'.
0x10484 FTDF_TX_CLEAR_OS_REG 32-bit — One shot register to clear flag
  [3:0] TX_FLAG_CLEAR wo — Tx meta data per entry: if set to '1', the tx_flag_stat will be cleared to '0'.
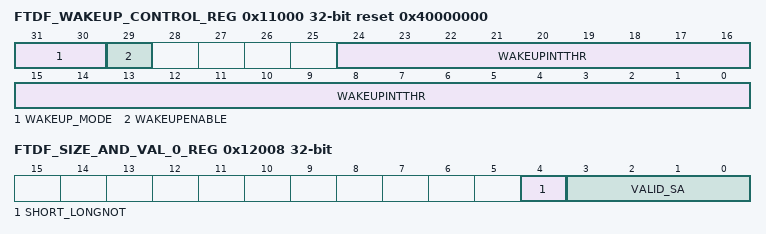
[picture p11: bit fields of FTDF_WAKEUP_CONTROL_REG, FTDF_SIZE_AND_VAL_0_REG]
0x11000 FTDF_WAKEUP_CONTROL_REG 32-bit reset 0x40000000 (reset mask 0x7FFFFFFF) — Wakeup timer vcontrol register
  [31:30] WAKEUP_MODE — The Control register WakeUp_mode controls the behavior of the Event counter: 0d = off, 1d = free running (default), 2d = one shot with auto clear, 3d = configurable period (timer mode).
  [29] WAKEUPENABLE — If set to '1', the WakeUpIntThr is enabled to generate an WAKEUP_IRQ interrupt.
  [24:0] WAKEUPINTTHR — Threshold for wake-up interrupt. When WakeUpEnable is set to '1' and the Wake-up (event) counter matches this value, the interrupt WAKEUP_IRQ is set to '1' for the duration of one LP_CLK period.
0x12000 FTDF_LONG_ADDR_0_0_REG 32-bit (reset mask 0x7FFFFFFF)
  [31:0] EXP_SA_L — Lowest part of the 64 bits long source address or SA entry 1 resp. SA entry 0 in case of short source address.
0x12004 FTDF_LONG_ADDR_1_0_REG 32-bit (reset mask 0x7FFFFFFF)
  [31:0] EXP_SA_H — Highest part of the 64 bits long source address or SA entry 3 resp. SA entry 2 in case of short source address.
0x12008 FTDF_SIZE_AND_VAL_0_REG 32-bit
  [4] SHORT_LONGNOT — A '1' indicates that Exp_SA contains four short SA's, a '0' indicates one long SA.
  [3:0] VALID_SA — Indication which SA entry is valid (if set). In case of 4 short SA Valid bit 3 belongs to SA entry 3 etc. In case of a long SA Valid bit 0 is the valid indication.
